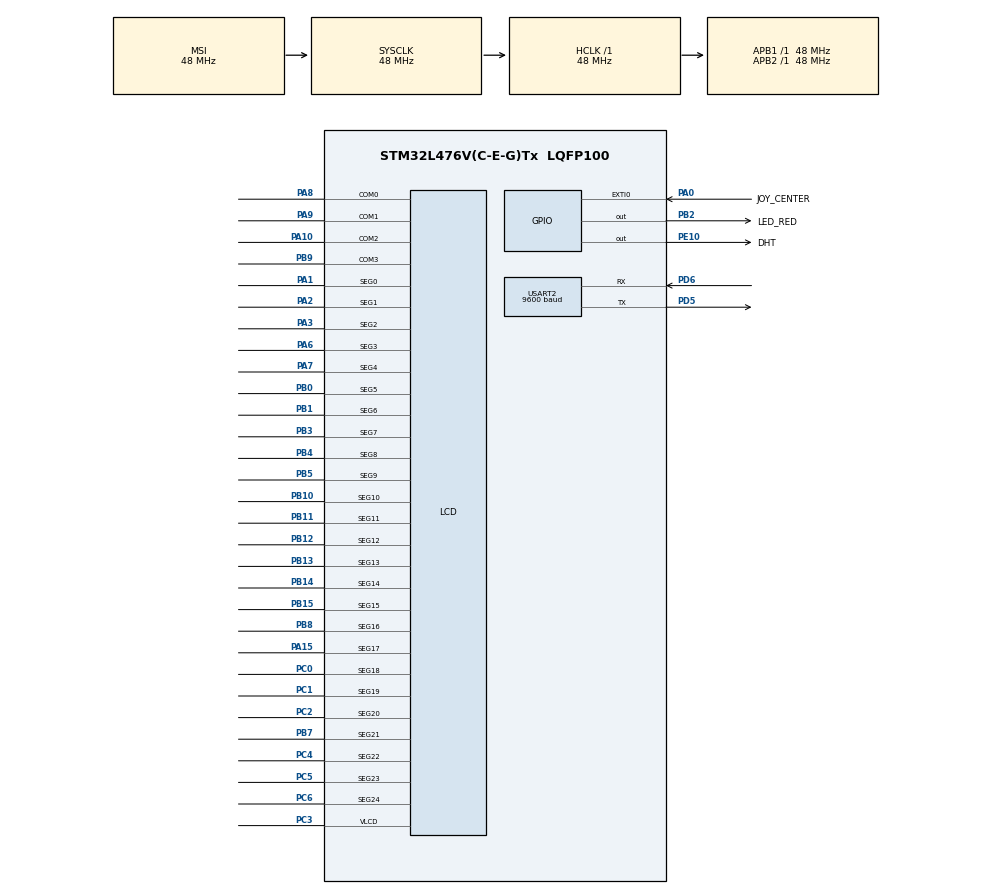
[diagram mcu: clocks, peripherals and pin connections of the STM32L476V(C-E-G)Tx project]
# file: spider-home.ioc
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LCD.Bias=LCD_BIAS_1_3
Mcu.Family=STM32L4
Mcu.Name=STM32L476V(C-E-G)Tx
Mcu.Package=LQFP100
NVIC.EXTI0_IRQn=true\:0\:0\:false\:false\:true\:true\:true\:true
NVIC.PriorityGroup=NVIC_PRIORITYGROUP_4
NVIC.RTC_WKUP_IRQn=true\:0\:0\:false\:false\:true\:true\:true\:true
PA0.GPIO_Label=JOY_CENTER
PA0.GPIO_ModeDefaultEXTI=GPIO_MODE_IT_FALLING
PA0.GPIO_PuPd=GPIO_NOPULL
PA0.Signal=GPXTI0
PA1.Mode=SEG0
PA1.Signal=LCD_SEG0
PA10.Mode=1/4 Duty Cycle
PA10.Signal=LCD_COM2
PA13\ (JTMS-SWDIO).Mode=Serial_Wire
PA13\ (JTMS-SWDIO).Signal=SYS_JTMS-SWDIO
PA14\ (JTCK-SWCLK).Mode=Serial_Wire
PA14\ (JTCK-SWCLK).Signal=SYS_JTCK-SWCLK
PA15\ (JTDI).Mode=SEG17
PA15\ (JTDI).Signal=LCD_SEG17
PA2.Mode=SEG1
PA2.Signal=LCD_SEG1
PA3.Mode=SEG2
PA3.Signal=LCD_SEG2
PA6.Mode=SEG3
PA6.Signal=LCD_SEG3
PA7.Mode=SEG4
PA7.Signal=LCD_SEG4
PA8.Mode=1/4 Duty Cycle
PA8.Signal=LCD_COM0
PA9.Mode=1/4 Duty Cycle
PA9.Signal=LCD_COM1
PB0.Mode=SEG5
PB0.Signal=LCD_SEG5
PB1.Mode=SEG6
PB1.Signal=LCD_SEG6
PB10.Mode=SEG10
PB10.Signal=LCD_SEG10
PB11.Mode=SEG11
PB11.Signal=LCD_SEG11
PB12.Mode=SEG12
PB12.Signal=LCD_SEG12
PB13.Mode=SEG13
PB13.Signal=LCD_SEG13
PB14.Mode=SEG14
PB14.Signal=LCD_SEG14
PB15.Mode=SEG15
PB15.Signal=LCD_SEG15
PB2.GPIO_Label=LED_RED
PB2.GPIO_PuPd=GPIO_PULLUP
PB2.GPIO_Speed=GPIO_SPEED_FREQ_VERY_HIGH
PB2.Signal=GPIO_Output
PB3\ (JTDO-TRACESWO).Mode=SEG7
PB3\ (JTDO-TRACESWO).Signal=LCD_SEG7
PB4\ (NJTRST).Mode=SEG8
PB4\ (NJTRST).Signal=LCD_SEG8
PB5.Mode=SEG9
PB5.Signal=LCD_SEG9
PB7.Mode=SEG21
PB7.Signal=LCD_SEG21
PB8.Mode=SEG16
PB8.Signal=LCD_SEG16
PB9.Mode=1/4 Duty Cycle
PB9.Signal=LCD_COM3
PC0.Mode=SEG18
PC0.Signal=LCD_SEG18
PC1.Mode=SEG19
PC1.Signal=LCD_SEG19
PC2.Mode=SEG20
PC2.Signal=LCD_SEG20
PC3.Mode=1/4 Duty Cycle
PC3.Signal=LCD_VLCD
PC4.Mode=SEG22
PC4.Signal=LCD_SEG22
PC5.Mode=SEG23
PC5.Signal=LCD_SEG23
PC6.Mode=SEG24
PC6.Signal=LCD_SEG24
PD5.Mode=Asynchronous
PD5.Signal=USART2_TX
PD6.Mode=Asynchronous
PD6.Signal=USART2_RX
PE10.GPIO_Label=DHT
PE10.GPIO_PuPd=GPIO_NOPULL
PE10.GPIO_Speed=GPIO_SPEED_FREQ_VERY_HIGH
PE10.PinState=GPIO_PIN_SET
PE10.Signal=GPIO_Output
ProjectManager.HeapSize=0x200
ProjectManager.StackSize=0x400
ProjectManager.TargetToolchain=Makefile
RCC.ADCFreq_Value=192000000
RCC.AHBFreq_Value=48000000
RCC.APB1Freq_Value=48000000
RCC.APB1TimFreq_Value=48000000
RCC.APB2Freq_Value=48000000
RCC.APB2TimFreq_Value=48000000
RCC.CortexFreq_Value=48000000
RCC.HCLKFreq_Value=48000000
RCC.HSE_VALUE=8000000
RCC.HSI_VALUE=16000000
RCC.LSE_VALUE=32768
RCC.MSIClockRange=RCC_MSIRANGE_11
RCC.MSI_VALUE=48000000
RCC.PREFETCH_ENABLE=1
RCC.SYSCLKFreq_VALUE=48000000
RCC.USBFreq_Value=192000000
RCC.VCOOutputFreq_Value=384000000
RTC.WakeUpClock-WakeUp=RTC_WAKEUPCLOCK_RTCCLK_DIV16
RTC.WakeUpCounter-WakeUp=1999
TIM2.AutoReloadPreload=TIM_AUTORELOAD_PRELOAD_ENABLE
TIM2.ClockDivision=TIM_CLOCKDIVISION_DIV1
TIM2.Prescaler=48-1
USART2.BaudRate=9600
USART2.VirtualMode-Asynchronous=VM_ASYNC
VP_RTC_VS_RTC_Activate.Mode=RTC_Enabled
VP_RTC_VS_RTC_WakeUp_intern.Mode=WakeUp
VP_TIM2_VS_ClockSourceINT.Mode=Internal
board=STM32L476G-DISCO

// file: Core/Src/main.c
/* USER CODE BEGIN Header */
/**
 ******************************************************************************
 * @file           : main.c
 * @brief          : Main program body
 ******************************************************************************
 * @attention
 *
 * Copyright (c) 2023 STMicroelectronics.
 * All rights reserved.
 *
 * This software is licensed under terms that can be found in the LICENSE file
 * in the root directory of this software component.
 * If no LICENSE file comes with this software, it is provided AS-IS.
 *
 ******************************************************************************
 */
/* USER CODE END Header */
#include "main.h"
#include "rtc.h"
#include "tim.h"
#include "usart.h"
#include "gpio.h"

/* USER CODE BEGIN Includes */

#include <Application/app.h>

/* USER CODE END Includes */

void SystemClock_Config(void);

int main(void)
{

  /* MCU Configuration--------------------------------------------------------*/

  /* Reset of all peripherals, Initializes the Flash interface and the Systick. */
  HAL_Init();

  /* Configure the system clock */
  SystemClock_Config();

  /* Initialize all configured peripherals */
  MX_GPIO_Init();
  MX_USART2_UART_Init();
  MX_TIM2_Init();
  MX_RTC_Init();
  /* USER CODE BEGIN 2 */

  run();

  /* USER CODE END 2 */

  /* Infinite loop */
  while (1)
  {

  }
}

void SystemClock_Config(void)
{
  RCC_OscInitTypeDef RCC_OscInitStruct = {0};
  RCC_ClkInitTypeDef RCC_ClkInitStruct = {0};

  /** Configure the main internal regulator output voltage
  */
  if (HAL_PWREx_ControlVoltageScaling(PWR_REGULATOR_VOLTAGE_SCALE1) != HAL_OK)
  {
    Error_Handler();
  }

  /** Initializes the RCC Oscillators according to the specified parameters
  * in the RCC_OscInitTypeDef structure.
  */
  RCC_OscInitStruct.OscillatorType = RCC_OSCILLATORTYPE_LSI|RCC_OSCILLATORTYPE_MSI;
  RCC_OscInitStruct.LSIState = RCC_LSI_ON;
  RCC_OscInitStruct.MSIState = RCC_MSI_ON;
  RCC_OscInitStruct.MSICalibrationValue = 0;
  RCC_OscInitStruct.MSIClockRange = RCC_MSIRANGE_11;
  RCC_OscInitStruct.PLL.PLLState = RCC_PLL_NONE;
  if (HAL_RCC_OscConfig(&RCC_OscInitStruct) != HAL_OK)
  {
    Error_Handler();
  }

  /** Initializes the CPU, AHB and APB buses clocks
  */
  RCC_ClkInitStruct.ClockType = RCC_CLOCKTYPE_HCLK|RCC_CLOCKTYPE_SYSCLK
                              |RCC_CLOCKTYPE_PCLK1|RCC_CLOCKTYPE_PCLK2;
  RCC_ClkInitStruct.SYSCLKSource = RCC_SYSCLKSOURCE_MSI;
  RCC_ClkInitStruct.AHBCLKDivider = RCC_SYSCLK_DIV1;
  RCC_ClkInitStruct.APB1CLKDivider = RCC_HCLK_DIV1;
  RCC_ClkInitStruct.APB2CLKDivider = RCC_HCLK_DIV1;

  if (HAL_RCC_ClockConfig(&RCC_ClkInitStruct, FLASH_LATENCY_2) != HAL_OK)
  {
    Error_Handler();
  }
}

void Error_Handler(void)
{
  __disable_irq();
  while (1)
  {
  }
}
